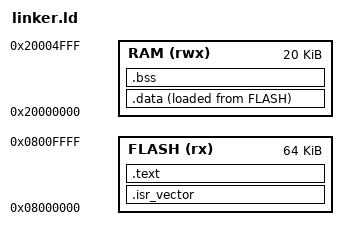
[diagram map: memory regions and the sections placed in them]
ENTRY(Reset_Handler)

MEMORY
{
    FLASH (rx)  : ORIGIN = 0x08000000, LENGTH = 64K
    RAM   (rwx) : ORIGIN = 0x20000000, LENGTH = 20K
}

_estack = ORIGIN(RAM) + LENGTH(RAM);

SECTIONS
{
    .isr_vector :
    {
        KEEP(*(.isr_vector))
    } > FLASH

    .text :
    {
        *(.text*)
        *(.rodata*)
        *(.ARM.extab* .gnu.linkonce.armextab.*)
        *(.ARM.exidx*)
    } > FLASH

    .data :
    {
        _sdata = .;
        *(.data*)
        _edata = .;
    } > RAM AT > FLASH

    _sidata = LOADADDR(.data);

    .bss :
    {
        _sbss = .;
        *(.bss*)
        *(COMMON)
        _ebss = .;
    } > RAM

    . = ALIGN(4);
    _end = .;

    ASSERT(_ebss < _estack, "RAM 溢出：.bss 已经顶到栈顶")
    ASSERT((_ebss + 0x400) <= _estack, "栈空间不足 1 KB")
}
